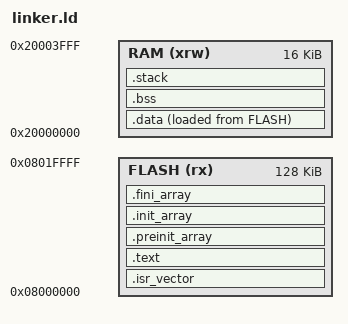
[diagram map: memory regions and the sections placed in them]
ENTRY(Reset_Handler)

MEMORY
{
    FLASH (rx)  : ORIGIN = 0x08000000, LENGTH = 128K
    RAM   (xrw) : ORIGIN = 0x20000000, LENGTH = 16K
}

_estack = ORIGIN(RAM) + LENGTH(RAM);

SECTIONS
{
    .isr_vector :
    {
        . = ALIGN(4);
        KEEP(*(.isr_vector))
    } > FLASH

    .text :
    {
        . = ALIGN(4);
        *(.text*)
        *(.rodata*)
        KEEP(*(.init))
        KEEP(*(.fini))
        . = ALIGN(4);
    } > FLASH

    .preinit_array :
    {
        PROVIDE_HIDDEN(__preinit_array_start = .);
        KEEP(*(.preinit_array*))
        PROVIDE_HIDDEN(__preinit_array_end = .);
    } > FLASH

    .init_array :
    {
        PROVIDE_HIDDEN(__init_array_start = .);
        KEEP(*(SORT(.init_array.*)))
        KEEP(*(.init_array*))
        PROVIDE_HIDDEN(__init_array_end = .);
    } > FLASH

    .fini_array :
    {
        PROVIDE_HIDDEN(__fini_array_start = .);
        KEEP(*(SORT(.fini_array.*)))
        KEEP(*(.fini_array*))
        PROVIDE_HIDDEN(__fini_array_end = .);
    } > FLASH

    INCLUDE "kernel.ld"

    _sidata = LOADADDR(.data);
    .data :
    {
        . = ALIGN(4);
        _sdata = .;
        *(.data*)
        . = ALIGN(4);
        _edata = .;
    } > RAM AT > FLASH

    .bss (NOLOAD) :
    {
        . = ALIGN(4);
        _sbss = .;
        *(.bss*)
        *(COMMON)
        . = ALIGN(4);
        _ebss = .;
        _end = .;
    } > RAM

    .stack (NOLOAD) :
    {
        . = ALIGN(8);
        . += 1024;
    } > RAM

    ASSERT(. <= _estack, "RAM overflow")
}
